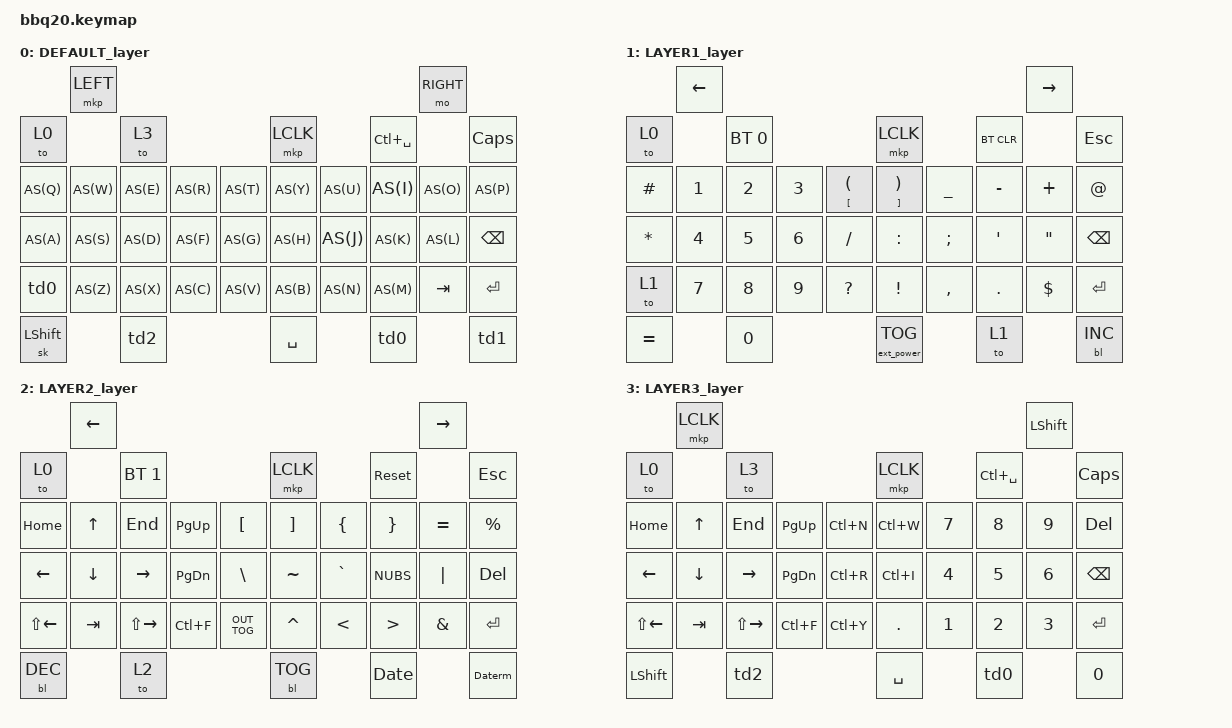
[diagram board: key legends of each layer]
/*
 * Copyright (c) 2023 ZitaoTech
 *
 * SPDX-License-Identifier: MIT
 */
 
#include <behaviors.dtsi>
#include <dt-bindings/zmk/keys.h>
#include <dt-bindings/zmk/bt.h>
#include <dt-bindings/zmk/outputs.h>
#include <dt-bindings/zmk/mouse.h>
#include <dt-bindings/zmk/backlight.h>
#include <dt-bindings/zmk/ext_power.h>

   
#define DEFAULT 0
#define LAYER1 1
#define LAYER2 2
#define LAYER3 3
#define LAYER4 4
#define LAYER5 5
#define LAYER6 6

/ {
    macros {
        Date: Date {
            compatible = "zmk,behavior-macro";
            label = "DATE";
            #binding-cells = <0>;
            bindings = <&kp SLASH &kp NUMBER_6 &kp SLASH &kp NUMBER_2 &kp NUMBER_0 &kp NUMBER_2 &kp NUMBER_4>;
        };

        Daterm: Daterm {
            compatible = "zmk,behavior-macro";
            label = "DATE";
            #binding-cells = <0>;
            bindings = <&kp SLASH &kp NUMBER_6 &kp SLASH &kp NUMBER_2 &kp NUMBER_0 &kp NUMBER_2 &kp NUMBER_4 &kp MINUS &kp LS(R) &kp LS(M)>;
        };

        BENLLW: BENLLW {
            compatible = "zmk,behavior-macro";
            label = "BENLLW";
            #binding-cells = <0>;
            bindings = <&kp B &kp E &kp N &kp L &kp L &kp W &kp AT &kp G &kp M &kp A &kp I &kp L &kp PERIOD &kp C &kp O &kp M>;
        };

        Joyce18889: Joyce18889 {
            compatible = "zmk,behavior-macro";
            label = "JOYCE18889";
            #binding-cells = <0>;
            bindings = <&kp J &kp O &kp Y &kp C &kp E &kp NUMBER_1 &kp NUMBER_8 &kp NUMBER_8 &kp NUMBER_8 &kp NUMBER_9 &kp AT_SIGN &kp G &kp M &kp A &kp I &kp L &kp PERIOD &kp C &kp O &kp M>;
        };

        macro_doherty: macro_doherty {
            label = "macro_doherty";
            compatible = "zmk,behavior-macro";
            #binding-cells = <0>;
            bindings =
                <&macro_tap>,
                <&kp B &kp E &kp N &kp DOT &kp L &kp E &kp E &kp AT &kp D &kp O &kp H &kp E &kp R &kp T &kp Y &kp DOT &kp C &kp O &kp DOT &kp U &kp K>;
        };

        teresachng: teresachng {
            compatible = "zmk,behavior-macro";
            label = "TERESACHNG";
            #binding-cells = <0>;
            bindings = <&kp T &kp E &kp R &kp E &kp S &kp A &kp M &kp G &kp C &kp H &kp N &kp G &kp AT_SIGN &kp G &kp M &kp A &kp I &kp L &kp PERIOD &kp C &kp O &kp M>;
        };

        ben: ben {
            compatible = "zmk,behavior-macro";
            label = "BEN";
            #binding-cells = <0>;
            bindings = <&kp MINUS &kp LS(B) &kp E &kp N>;
        };

        atDoherty: atDoherty {
            compatible = "zmk,behavior-macro";
            #binding-cells = <0>;
            bindings = <&kp AT_SIGN &kp D &kp O &kp H &kp E &kp R &kp T &kp Y &kp PERIOD &kp C &kp O &kp PERIOD &kp U &kp K>;
        };

        Brackets: Brackets {
            compatible = "zmk,behavior-macro";
            #binding-cells = <0>;
            bindings = <&kp LEFT_PARENTHESIS &kp RIGHT_PARENTHESIS &kp LEFT>;
        };

        ArrowBrackets: ArrowBrackets {
            compatible = "zmk,behavior-macro";
            #binding-cells = <0>;
            bindings = <&kp LESS_THAN &kp GREATER_THAN &kp LEFT>;
        };

        SquareBrackets: SquareBrackets {
            compatible = "zmk,behavior-macro";
            #binding-cells = <0>;
            bindings = <&kp LEFT_BRACKET &kp RIGHT_BRACKET &kp LEFT>;
        };

        Applehome: Applehome {
            compatible = "zmk,behavior-macro";
            #binding-cells = <0>;
            bindings = <&kt CLCK &kp H &kt CLCK>;
        };

        Applesearch: Applesearch {
            compatible = "zmk,behavior-macro";
            #binding-cells = <0>;
            bindings = <&kt CLCK &kp S &kt CLCK>;
        };
    };
};






/ {
    behaviors {
        td0: tap_dance_0 {
            compatible = "zmk,behavior-tap-dance";
            #binding-cells = <0>;
            tapping-term-ms = <400>;
            bindings = <&sl LAYER1>, <&to 1>;
        };

        td1: tap_dance_1 {
            compatible = "zmk,behavior-tap-dance";
            #binding-cells = <0>;
            tapping-term-ms = <400>;
            bindings = <&sk LSHFT>, <&kp CLCK>;
        };

        td2: tap_dance_2 {
            compatible = "zmk,behavior-tap-dance";
            #binding-cells = <0>;
            tapping-term-ms = <400>;
            bindings = <&sl LAYER2>, <&to 2>;
        };

    };
    behaviors {
        hm: homerow_mods {
            compatible = "zmk,behavior-hold-tap";
            #binding-cells = <2>;
            tapping-term-ms = <500>;
            bindings = <&out &kp>;
        };
    };

#define AS(keycode) &as LS(keycode) keycode
        behaviors {
            as: auto_shift {
                compatible = "zmk,behavior-hold-tap";
                label = "AUTO_SHIFT";
                #binding-cells = <2>;
                tapping_term_ms = <250>;
                quick_tap_ms = <0>;
                flavor = "tap-preferred";
                bindings = <&kp>, <&kp>;
            };
        };



    keymap {
        compatible = "zmk,keymap";

        DEFAULT_layer {

            bindings = <
//         --------------------------------------------------------------------------------------------------------------------------         
//         |    Shoulder Key1    |                                                                             |    Shoulder Key2    |     
// |         Call key      |      Blackberry Key        |    Trackpad    |             Back Key                |             Endcall Key          |
// |     Q      |     W    |     E    |     R    |      T      |       Y        |       U        |        I        |       O      |      P        |     
// |     A      |     S    |     D    |     F    |      G      |       H        |       J        |        K        |       L      |      ←        |  
// |     alt    |     Z    |     X    |     C    |      V      |       B        |       N        |        M        |       $      |    Enter      |   
//        |         aA     |         0           |           SPACE              |         SYM         |        aA          |       
//        -----------------------------------------------------------------------------------------------------------------

                 &mkp LEFT                                                                                          &mo RIGHT
    &to 0                   &to 3                          &mkp LCLK                          &kp LC(SPACE)                         &kp CLCK
    AS(Q)        AS(W)      AS(E)       AS(R)     AS(T)         AS(Y)             AS(U)            AS(I)            AS(O)            AS(P)
    AS(A)        AS(S)      AS(D)       AS(F)     AS(G)         AS(H)             AS(J)            AS(K)            AS(L)            &kp BSPC
    &td0         AS(Z)      AS(X)       AS(C)     AS(V)         AS(B)             AS(N)            AS(M)            &kp TAB          &kp ENTER
    &sk LSHFT               &td2                                &kp SPACE                          &td0                              &td1
            >;
        };



        LAYER1_layer {

            bindings = <        
                 &kp LEFT                                                                                          &kp RIGHT
    &to 0                   &bt BT_SEL 0                        &mkp LCLK                          &bt BT_CLR                        &kp ESC
    &kp HASH     &kp N1     &kp N2      &kp N3    &mt LBKT LPAR &mt RBKT RPAR     &kp UNDER        &kp MINUS        &kp PLUS         &kp AT
    &kp STAR     &kp N4     &kp N5      &kp N6    &kp SLASH     &kp COLON         &kp SEMI         &kp APOS         &kp DQT          &kp BSPC
    &to 1        &kp N7     &kp N8      &kp N9    &kp QMARK     &kp EXCL          &kp COMMA        &kp DOT          &kp DLLR         &kp ENTER
    &kp EQUAL               &kp N0                              &ext_power EP_TOG                  &to 1                             &bl BL_INC
            >;
        };

        LAYER2_layer {

            bindings = <
                        &kp LEFT                                                                                                    &kp RIGHT
    &to 0                   &bt BT_SEL 1                     &mkp LCLK                                      &sys_reset                       &kp ESC
    &kp HOME     &kp UP     &kp END        &kp PG_UP         &kp LBKT     &kp RBKT          &kp LBRC        &kp RBRC        &kp EQUAL        &kp PRCNT
    &kp LEFT     &kp DOWN   &kp RIGHT      &kp PG_DN         &kp BSLH     &kp TILDE         &kp GRAVE       &kp NUBS        &kp PIPE         &kp DEL
    &kp LS(LEFT) &kp TAB    &kp LS(RIGHT)  &kp LC(F)         &kp OUT_TOG      &kp CARET         &kp LT          &kp GT          &kp AMPS         &kp ENTER
    &bl BL_DEC              &to 2                            &bl BL_TOG                                     &Date                            &Daterm
            >;
        };

        LAYER3_layer {

            bindings = <        
                 &mkp LCLK                                                                                       &kp LSHFT
    &to 0                   &to 3                  &mkp LCLK                                    &kp LC(SPACE)                   &kp CLCK
    &kp HOME     &kp UP     &kp END        &kp PG_UP    &kp LC(N)        &kp LC(W)        &kp N7     &kp N8      &kp N9          &kp DEL
    &kp LEFT     &kp DOWN   &kp RIGHT      &kp PG_DN    &kp LC(R)        &kp LC(I)        &kp N4     &kp N5      &kp N6          &kp BSPC
    &kp LS(LEFT) &kp TAB    &kp LS(RIGHT)  &kp LC(F)    &kp LC(Y)        &kp DOT          &kp N1     &kp N2      &kp N3          &kp ENTER
    &kp LSHFT               &td2                        &kp SPACE                                    &td0                        &kp N0
            >;
        };

    };
};

